# STM32G0C1 register map
File version: 1.8
CPU: CM0 r0p1, little endian, MPU, no FPU, 2 interrupt priority bits
Registers are 32-bit, read-write, reset 0x0 unless marked. A register's access mark holds for its fields unless they carry their own. Offsets are from the block's base; [hi:lo] are bit positions; {n}, {i} and the like mark numbered series; 'fields as' and 'values as' point back to an identical list.

## AES — Advanced Encryption Standard
Base 0x40026000
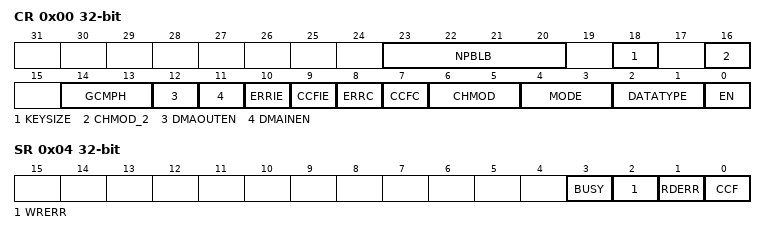
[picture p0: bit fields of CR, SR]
0x00 CR — AES control register
  [23:20] NPBLB — Number of padding bytes in last block The bitfield sets the number of padding bytes in last block of payload: ...
  [18] KEYSIZE — Key size selection This bitfield defines the length of the key used in the AES cryptographic core, in bits: Attempts to write the bit are ignored when the EN bit of the AES_CR register is set before the write access and it is not cleared by that write access.
    0=AES128 (128); 1=AES256 (256)
  [16] CHMOD_2 — Chaining mode selection, bit [2] Refer to the bits [5:6] of the register for the description of the CHMOD[2:0] bitfield CHMOD[1:0]: Chaining mode selection, bits [1:0] This bitfield, together with the bit CHMOD[2] forming CHMOD[2:0], selects the AES chaining mode: others: Reserved Attempts to write the bitfield are ignored when the EN bit of the AES_CR register is set before the write access and it is not cleared by that write access.
    0=CHMOD (Mode as per CHMOD (ECB, CBC, CTR, GCM)); 1=CCM (Counter with CBC-MAC (CCM) - CHMOD must be 0 (ECB))
  [14:13] GCMPH — GCM or CCM phase selection This bitfield selects the phase of GCM, GMAC or CCM algorithm: The bitfield has no effect if other than GCM, GMAC or CCM algorithms are selected (through the ALGOMODE bitfield).
    0=Init phase; 1=Header phase; 2=Payload phase; 3=Final Phase
  [12] DMAOUTEN — DMA output enable This bit enables/disables data transferring with DMA, in the output phase: When the bit is set, DMA requests are automatically generated by AES during the output data phase. This feature is only effective when Mode 1 or Mode 3 is selected through the MODE[1:0] bitfield. It is not effective for Mode 2 (key derivation). Usage of DMA with Mode 4 (single decryption) is not recommended.
    0=Disable DMA Output; 1=Enabled DMA Output
  [11] DMAINEN — DMA input enable This bit enables/disables data transferring with DMA, in the input phase: When the bit is set, DMA requests are automatically generated by AES during the input data phase. This feature is only effective when Mode 1 or Mode 3 is selected through the MODE[1:0] bitfield. It is not effective for Mode 2 (key derivation). Usage of DMA with Mode 4 (single decryption) is not recommended.
    0=Disable DMA Input; 1=Enable DMA Input
  [10] ERRIE — Error interrupt enable This bit enables or disables (masks) the AES interrupt generation when RDERR and/or WRERR is set:
    0=Disabled (Disable (mask) error interrupt); 1=Enabled (Enable error interrupt)
  [9] CCFIE — CCF interrupt enable This bit enables or disables (masks) the AES interrupt generation when CCF (computation complete flag) is set:
    0=Disabled (Disable (mask) CCF interrupt); 1=Enabled (Enable CCF interrupt)
  [8] ERRC — Error flag clear Upon written to 1, this bit clears the RDERR and WRERR error flags in the AES_SR register: Reading the flag always returns zero.
    on write: 1=Clear RDERR and WRERR flags
  [7] CCFC — Computation complete flag clear Upon written to 1, this bit clears the computation complete flag (CCF) in the AES_SR register: Reading the flag always returns zero.
    on write: 1=Clear computation complete flag
  [6:5] CHMOD — Chaining mode selection, bit [2] Refer to the bits [5:6] of the register for the description of the CHMOD[2:0] bitfield CHMOD[1:0]: Chaining mode selection, bits [1:0] This bitfield, together with the bit CHMOD[2] forming CHMOD[2:0], selects the AES chaining mode: others: Reserved Attempts to write the bitfield are ignored when the EN bit of the AES_CR register is set before the write access and it is not cleared by that write access.
    0=ECB (Electronic codebook (ECB) / Counter with CBC-MAC (CCM) if CHMOD2 is 1); 1=CBC (Cipher-block chaining (CBC)); 2=CTR (Counter mode (CTR)); 3=GCM (Galois counter mode (GCM) and Galois message authentication code (GMAC))
  [4:3] MODE — AES operating mode This bitfield selects the AES operating mode: Attempts to write the bitfield are ignored when the EN bit of the AES_CR register is set before the write access and it is not cleared by that write access. Any attempt to selecting Mode 4 while either ECB or CBC chaining mode is not selected, defaults to effective selection of Mode 3. It is not possible to select a Mode 3 following a Mode 4.
    0=Mode 1: encryption; 1=Mode 2: key derivation (or key preparation for ECB/CBC decryption); 2=Mode 3: decryption; 3=Mode 4: key derivation then single decryption
  [2:1] DATATYPE — Data type selection This bitfield defines the format of data written in the AES_DINR register or read from the AES_DOUTR register, through selecting the mode of data swapping: For more details, refer to . Attempts to write the bitfield are ignored when the EN bit of the AES_CR register is set before the write access and it is not cleared by that write access.
    0=None (Word); 1=Half-word (16-bit); 2=Byte (8-bit); 3=Bit
  [0] EN — AES enable This bit enables/disables the AES peripheral: At any moment, clearing then setting the bit re-initializes the AES peripheral. This bit is automatically cleared by hardware upon the completion of the key preparation (Mode 2) and upon the completion of GCM/GMAC/CCM initial phase.
    0=Disabled (Disable AES); 1=Enabled (Enable AES)
0x04 SR ro — AES status register
  [3] BUSY
    0=Idle; 1=Busy
  [2] WRERR — Write error This flag indicates the detection of an unexpected write operation to the AES_DINR register (during computation or data output phase): The flag is set by hardware. It is cleared by software upon setting the ERRC bit of the AES_CR register. Upon the flag setting, an interrupt is generated if enabled through the ERRIE bit of the AES_CR register. The flag setting has no impact on the AES operation. Unexpected write is ignored.
    0=NoError (Write error not detected); 1=Error (Write error detected)
  [1] RDERR — Read error flag This flag indicates the detection of an unexpected read operation from the AES_DOUTR register (during computation or data input phase): The flag is set by hardware. It is cleared by software upon setting the ERRC bit of the AES_CR register. Upon the flag setting, an interrupt is generated if enabled through the ERRIE bit of the AES_CR register. The flag setting has no impact on the AES operation. Unexpected read returns zero.
    0=NoError (Read error not detected); 1=Error (Read error detected)
  [0] CCF — Computation completed flag This flag indicates whether the computation is completed: The flag is set by hardware upon the completion of the computation. It is cleared by software, upon setting the CCFC bit of the AES_CR register. Upon the flag setting, an interrupt is generated if enabled through the CCFIE bit of the AES_CR register. The flag is significant only when the DMAOUTEN bit is 0. It may stay high when DMA_EN is 1.
    0=Complete (Computation complete); 1=NotComplete (Computation not complete)
0x08 DINR — AES data input register
  [31:0] DIN — Input data word A four-fold sequential write to this bitfield during the input phase results in writing a complete 128-bit block of input data to the AES peripheral. From the first to the fourth write, the corresponding data weights are [127:96], [95:64], [63:32], and [31:0]. Upon each write, the data from the 32-bit input buffer are handled by the data swap block according to the DATATYPE[1:0] bitfield, then written into the AES core 128-bit input buffer. The data signification of the input data block depends on the AES operating mode: - Mode 1 (encryption): plaintext - Mode 2 (key derivation): the bitfield is not used (AES_KEYRx registers used for input) - Mode 3 (decryption) and Mode 4 (key derivation then single decryption): ciphertext The data swap operation is described in page499.
0x0C DOUTR ro — AES data output register
  [31:0] DOUT — Output data word This read-only bitfield fetches a 32-bit output buffer. A four-fold sequential read of this bitfield, upon the computation completion (CCF set), virtually reads a complete 128-bit block of output data from the AES peripheral. Before reaching the output buffer, the data produced by the AES core are handled by the data swap block according to the DATATYPE[1:0] bitfield. Data weights from the first to the fourth read operation are: [127:96], [95:64], [63:32], and [31:0]. The data signification of the output data block depends on the AES operating mode: - Mode 1 (encryption): ciphertext - Mode 2 (key derivation): the bitfield is not used (AES_KEYRx registers used for output) - Mode 3 (decryption) and Mode 4 (key derivation then single decryption): plaintext The data swap operation is described in page499.
0x10 KEYR0 — AES key register 0
  [31:0] KEY — Cryptographic key, bits [31:0] This bitfield contains the bits [31:0] of the AES encryption or decryption key, depending on the operating mode: - In Mode 1 (encryption), Mode 2 (key derivation) and Mode 4 (key derivation then single decryption): the value to write into the bitfield is the encryption key. - In Mode 3 (decryption): the value to write into the bitfield is the encryption key to be derived before being used for decryption. After writing the encryption key into the bitfield, its reading before enabling AES returns the same value. Its reading after enabling AES and after the CCF flag is set returns the decryption key derived from the encryption key. Note: In mode 4 (key derivation then single decryption) the bitfield always contains the encryption key. The AES_KEYRx registers may be written only when KEYSIZE value is correct and when the AES peripheral is disabled (EN bit of the AES_CR register cleared). Note that, if, the key is directly loaded to AES_KEYRx registers (hence writes to key register is ignored and KEIF is set). Refer to for more details.
{0x10+4i} KEYR{i} (i=1..3) — AES key register {i}
  [31:0] KEY — Cryptographic key, bits [{32i+31}:{32i}] Refer to the AES_KEYR0 register for description of the KEY[255:0] bitfield.
0x20 IVR0 — AES initialization vector register 0
  [31:0] IVI — Initialization vector input, bits [31:0] Refer to for description of the IVI[127:0] bitfield. The initialization vector is only used in chaining modes other than ECB. The AES_IVRx registers may be written only when the AES peripheral is disabled
{0x20+4i} IVR{i} (i=1..3) — AES initialization vector register {i}
  [31:0] IVI — Initialization vector input, bits [{32i+31}:{32i}] Refer to the AES_IVR0 register for description of the IVI[128:0] bitfield.
{0x20+4i} KEYR{i} (i=4..7) — AES key register {i}
  fields as KEYR1
{0x40+4i} SUSP{i}R (i=0..7) — AES suspend registers
  [31:0] SUSP — AES suspend Upon suspend operation, this bitfield of every AES_SUSPxR register takes the value of one of internal AES registers.
